# N32H7xx register map
Vendor: Nationstech Ltd.; File version: 1.0
CPU: CM7 r1p1, little endian, MPU, FPU, 4 interrupt priority bits
Registers are 32-bit, read-write, reset 0x0 unless marked. A register's access mark holds for its fields unless they carry their own. Offsets are from the block's base; [hi:lo] are bit positions; {n}, {i} and the like mark numbered series; 'fields as' and 'values as' point back to an identical list.

## AHB_CACHE_PARMON — AHB cache parity monitor
Base 0x40045000
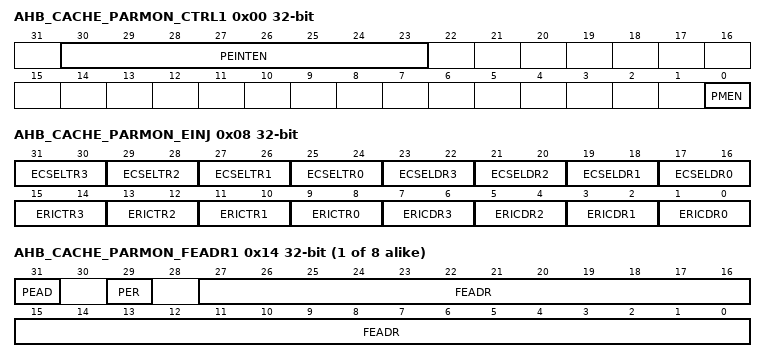
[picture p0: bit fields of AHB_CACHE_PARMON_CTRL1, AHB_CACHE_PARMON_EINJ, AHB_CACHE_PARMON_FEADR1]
0x00 AHB_CACHE_PARMON_CTRL1 — Parity monitor control register 1
  [30:23] PEINTEN, [0] PMEN
0x04 AHB_CACHE_PARMON_CTRL2 — Parity monitor control register 2
  [30:23] PFOEN
0x08 AHB_CACHE_PARMON_EINJ — Parity monitor error injection register
  [2n+25:2n+24] ECSELTR{n} (n=0..3), [2n+17:2n+16] ECSELDR{n} (n=0..3), [2n+9:2n+8] ERICTR{n} (n=0..3), [2n+1:2n] ERICDR{n} (n=0..3)
0x0C AHB_CACHE_PARMON_INTFS ro — Parity monitor interrupt flag shadow register
  [23:16] PEIF
0x10 AHB_CACHE_PARMON_INTF1 — Parity monitor memory 1 interrupt flag register
  [3] PEDCIFR
{0x0+0x14*i} AHB_CACHE_PARMON_FEADR{i} (i=1..8) — Parity monitor memory {i} fail event address register
  [31] PEAD, [29] PER, [27:0] FEADR ro
{0x4+0x14*i} AHB_CACHE_PARMON_FEDAT{i} ro (i=1..8) — Parity monitor memory {i} fail event data register
  [31:0] PEDAT
{0xC+0x14*i} AHB_CACHE_PARMON_FECOD{i} ro (i=1..8) — Parity monitor memory {i} fail event code register
  [15:0] PECOD
0x24 AHB_CACHE_PARMON_INTF2 — Parity monitor memory 2 interrupt flag register
  [3] PEDCIFR
0x38 AHB_CACHE_PARMON_INTF3 — Parity monitor memory 3 interrupt flag register
  [3] PEDCIFR
0x4C AHB_CACHE_PARMON_INTF4 — Parity monitor memory 4 interrupt flag register
  [3] PEDCIFR
0x60 AHB_CACHE_PARMON_INTF5 — Parity monitor memory 5 interrupt flag register
  [3] PEDCIFR
0x74 AHB_CACHE_PARMON_INTF6 — Parity monitor memory 6 interrupt flag register
  [3] PEDCIFR
0x88 AHB_CACHE_PARMON_INTF7 — Parity monitor memory 7 interrupt flag register
  [3] PEDCIFR
0x9C AHB_CACHE_PARMON_INTF8 — Parity monitor memory 8 interrupt flag register
  [3] PEDCIFR

## DMAMUX1 — DMA request multiplexer
Base 0x40046400
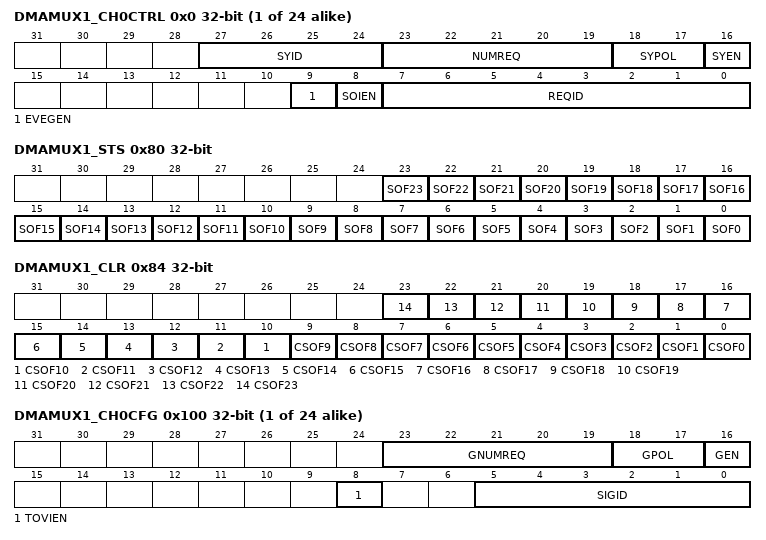
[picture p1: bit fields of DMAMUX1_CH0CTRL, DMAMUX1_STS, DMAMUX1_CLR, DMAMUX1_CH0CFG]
{0x0+4i} DMAMUX1_CH{i}CTRL (i=0..23) — nan
  [27:24] SYID, [23:19] NUMREQ, [18:17] SYPOL, [16] SYEN, [9] EVEGEN, [8] SOIEN, [7:0] REQID
0x80 DMAMUX1_STS ro — nan
  [n] SOF{n} (n=0..23)
0x84 DMAMUX1_CLR wo — nan
  [n] CSOF{n} (n=0..23)
{0x100+4i} DMAMUX1_CH{i}CFG (i=0..23) — nan
  [23:19] GNUMREQ, [18:17] GPOL, [16] GEN, [8] TOVIEN, [5:0] SIGID
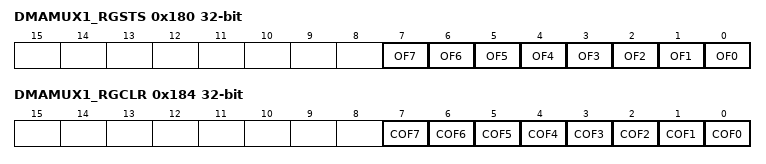
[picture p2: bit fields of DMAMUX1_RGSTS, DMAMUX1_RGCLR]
0x180 DMAMUX1_RGSTS ro — nan
  [n] OF{n} (n=0..7)
0x184 DMAMUX1_RGCLR wo — nan
  [n] COF{n} (n=0..7)

## DMAMUX2 — DMA request multiplexer
Base 0x51120000
Registers as DMAMUX1 (with DMAMUX1 read as DMAMUX2), without DMAMUX1_CH{n}CTRL (n=16..23), DMAMUX1_CH{n}CFG (n=16..23); these are added or differ:
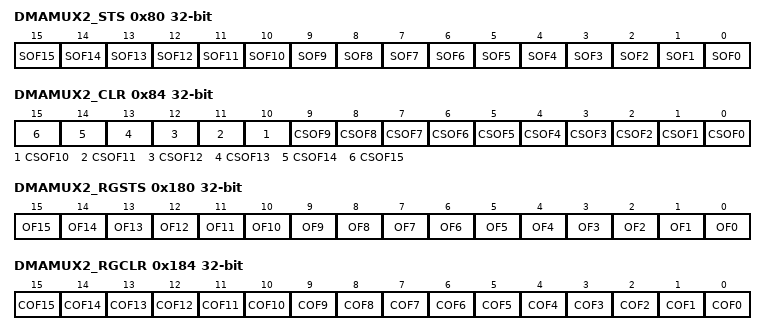
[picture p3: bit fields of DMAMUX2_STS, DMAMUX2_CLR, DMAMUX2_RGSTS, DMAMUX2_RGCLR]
0x80 DMAMUX2_STS ro — nan
  [n] SOF{n} (n=0..15)
0x84 DMAMUX2_CLR wo — nan
  [n] CSOF{n} (n=0..15)
0x180 DMAMUX2_RGSTS ro — nan
  [n] OF{n} (n=0..15)
0x184 DMAMUX2_RGCLR wo — nan
  [n] COF{n} (n=0..15)

## DMA1 — DMA controller 1
Base 0x40046800
Same registers: DMA2 0x40046C00, DMA3 0x40047000
{0x0+0x58*i} DMA_CH{i}SA (i=0..7)
  [31:0] ADDR
{0x8+0x58*i} DMA_CH{i}DA (i=0..7)
  [31:0] ADDR
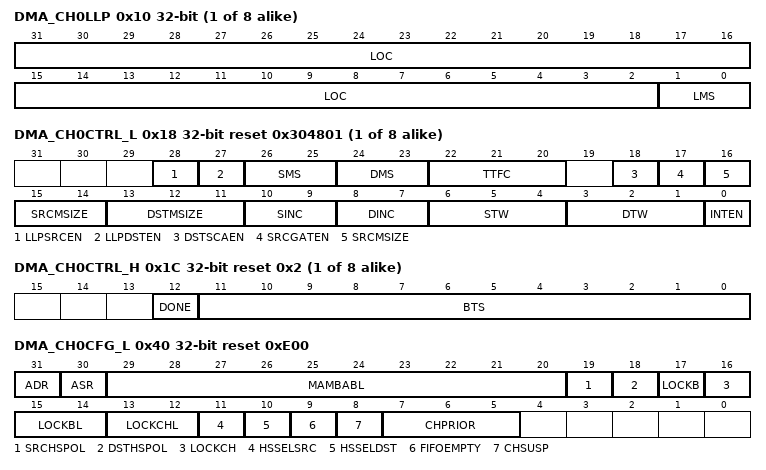
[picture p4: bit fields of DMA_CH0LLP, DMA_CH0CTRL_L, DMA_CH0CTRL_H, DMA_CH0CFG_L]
{0x10+0x58*i} DMA_CH{i}LLP (i=0..7)
  [31:2] LOC, [1:0] LMS
{0x18+0x58*i} DMA_CH{i}CTRL_L reset 0x304801 (i=0..7)
  [28] LLPSRCEN, [27] LLPDSTEN, [26:25] SMS, [24:23] DMS, [22:20] TTFC, [18] DSTSCAEN, [17] SRCGATEN, [16:14] SRCMSIZE, [13:11] DSTMSIZE, [10:9] SINC, [8:7] DINC, [6:4] STW, [3:1] DTW, [0] INTEN
{0x1C+0x58*i} DMA_CH{i}CTRL_H reset 0x2 (i=0..7)
  [12] DONE, [11:0] BTS
0x40 DMA_CH0CFG_L reset 0xE00
  [31] ADR, [30] ASR, [29:20] MAMBABL, [19] SRCHSPOL, [18] DSTHSPOL, [17] LOCKB, [16] LOCKCH, [15:14] LOCKBL, [13:12] LOCKCHL, [11] HSSELSRC, [10] HSSELDST, [9] FIFOEMPTY ro, [8] CHSUSP, [7:5] CHPRIOR
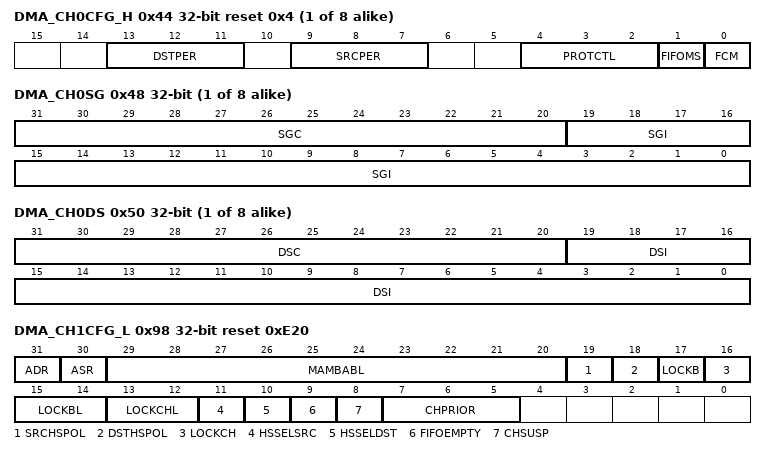
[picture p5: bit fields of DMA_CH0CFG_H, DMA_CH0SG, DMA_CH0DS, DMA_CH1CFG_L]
{0x44+0x58*i} DMA_CH{i}CFG_H reset 0x4 (i=0..7)
  [13:11] DSTPER, [9:7] SRCPER, [4:2] PROTCTL, [1] FIFOMS, [0] FCM
{0x48+0x58*i} DMA_CH{i}SG (i=0..7)
  [31:20] SGC, [19:0] SGI
{0x50+0x58*i} DMA_CH{i}DS (i=0..7)
  [31:20] DSC, [19:0] DSI
0x98 DMA_CH1CFG_L reset 0xE20
  fields as DMA_CH0CFG_L
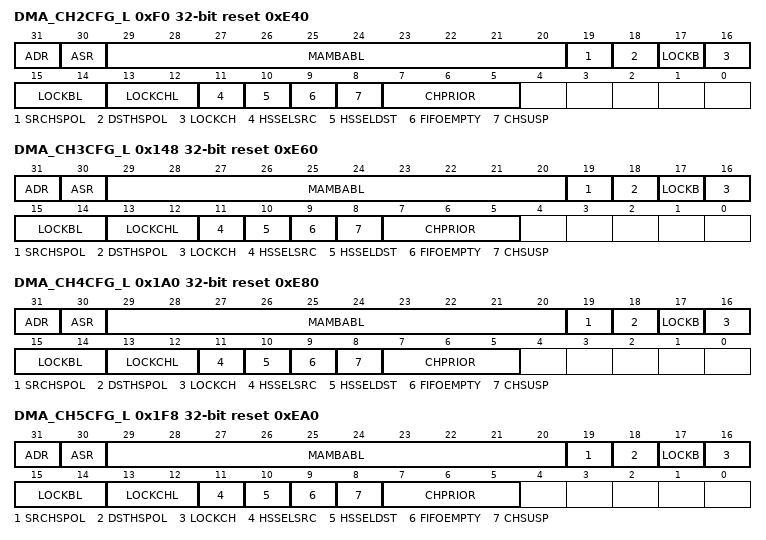
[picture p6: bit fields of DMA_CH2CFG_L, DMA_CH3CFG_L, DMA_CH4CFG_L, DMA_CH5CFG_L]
0xF0 DMA_CH2CFG_L reset 0xE40
  fields as DMA_CH0CFG_L
0x148 DMA_CH3CFG_L reset 0xE60
  fields as DMA_CH0CFG_L
0x1A0 DMA_CH4CFG_L reset 0xE80
  fields as DMA_CH0CFG_L
0x1F8 DMA_CH5CFG_L reset 0xEA0
  fields as DMA_CH0CFG_L
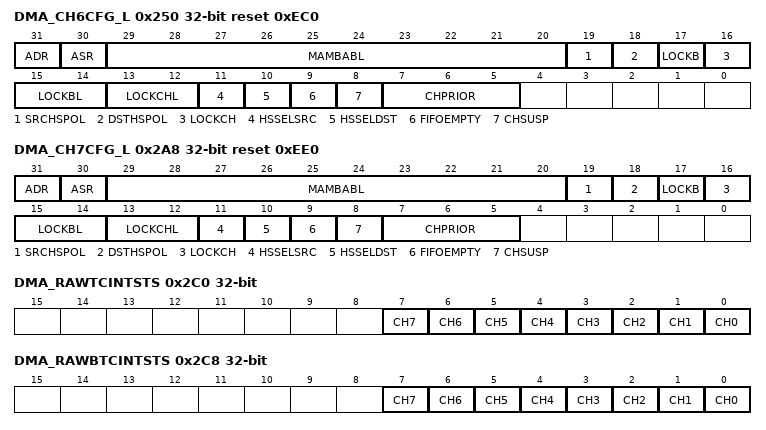
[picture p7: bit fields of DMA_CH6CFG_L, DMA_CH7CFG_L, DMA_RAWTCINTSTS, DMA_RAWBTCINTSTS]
0x250 DMA_CH6CFG_L reset 0xEC0
  fields as DMA_CH0CFG_L
0x2A8 DMA_CH7CFG_L reset 0xEE0
  fields as DMA_CH0CFG_L
0x2C0 DMA_RAWTCINTSTS
  [n] CH{n} (n=0..7)
0x2C8 DMA_RAWBTCINTSTS
  [n] CH{n} (n=0..7)
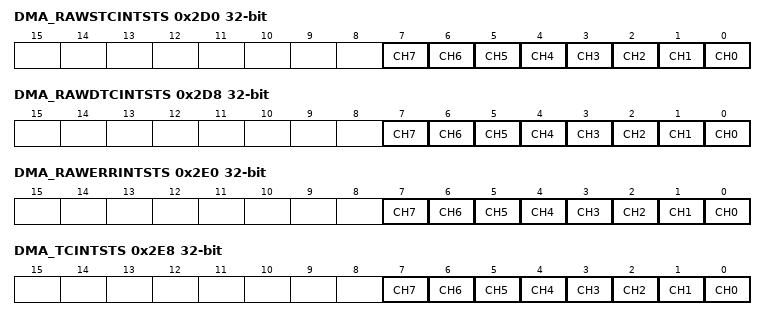
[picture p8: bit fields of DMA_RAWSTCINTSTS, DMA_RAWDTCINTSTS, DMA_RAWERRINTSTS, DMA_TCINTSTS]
0x2D0 DMA_RAWSTCINTSTS
  [n] CH{n} (n=0..7)
0x2D8 DMA_RAWDTCINTSTS
  [n] CH{n} (n=0..7)
0x2E0 DMA_RAWERRINTSTS
  [n] CH{n} (n=0..7)
0x2E8 DMA_TCINTSTS ro
  [n] CH{n} (n=0..7)
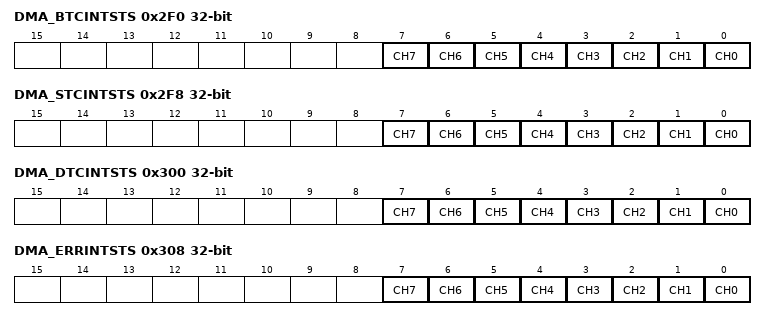
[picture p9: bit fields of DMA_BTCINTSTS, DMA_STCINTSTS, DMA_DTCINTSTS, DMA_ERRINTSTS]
0x2F0 DMA_BTCINTSTS ro
  [n] CH{n} (n=0..7)
0x2F8 DMA_STCINTSTS ro
  [n] CH{n} (n=0..7)
0x300 DMA_DTCINTSTS ro
  [n] CH{n} (n=0..7)
0x308 DMA_ERRINTSTS ro
  [n] CH{n} (n=0..7)
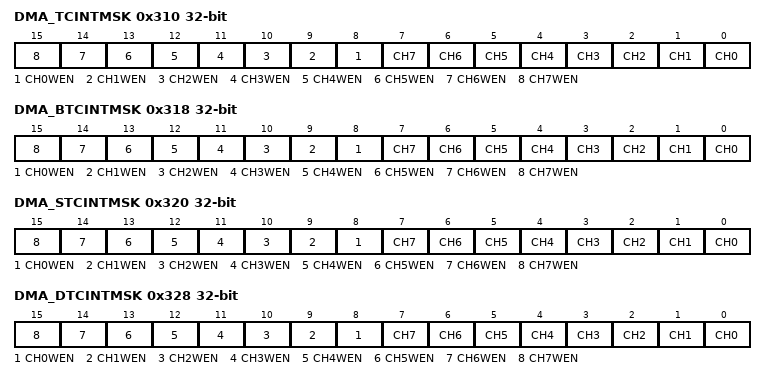
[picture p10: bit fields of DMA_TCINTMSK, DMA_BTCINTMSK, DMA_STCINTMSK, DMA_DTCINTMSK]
0x310 DMA_TCINTMSK
  [n+8] CH{n}WEN wo (n=0..7), [n] CH{n} (n=0..7)
0x318 DMA_BTCINTMSK
  [n+8] CH{n}WEN wo (n=0..7), [n] CH{n} (n=0..7)
0x320 DMA_STCINTMSK
  [n+8] CH{n}WEN wo (n=0..7), [n] CH{n} (n=0..7)
0x328 DMA_DTCINTMSK
  [n+8] CH{n}WEN wo (n=0..7), [n] CH{n} (n=0..7)
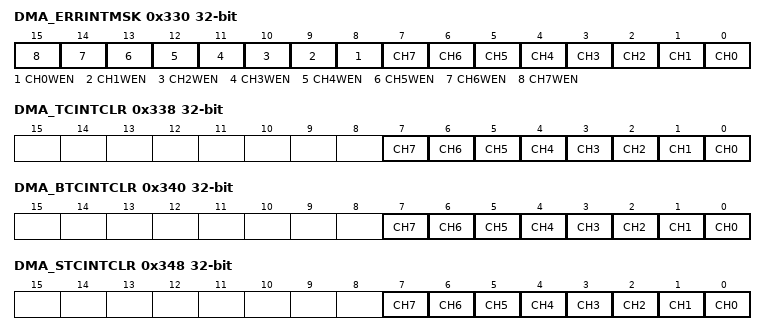
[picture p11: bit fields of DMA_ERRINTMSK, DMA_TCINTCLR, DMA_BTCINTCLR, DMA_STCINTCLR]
0x330 DMA_ERRINTMSK
  [n+8] CH{n}WEN wo (n=0..7), [n] CH{n} (n=0..7)
0x338 DMA_TCINTCLR wo
  [n] CH{n} (n=0..7)
0x340 DMA_BTCINTCLR wo
  [n] CH{n} (n=0..7)
0x348 DMA_STCINTCLR wo
  [n] CH{n} (n=0..7)
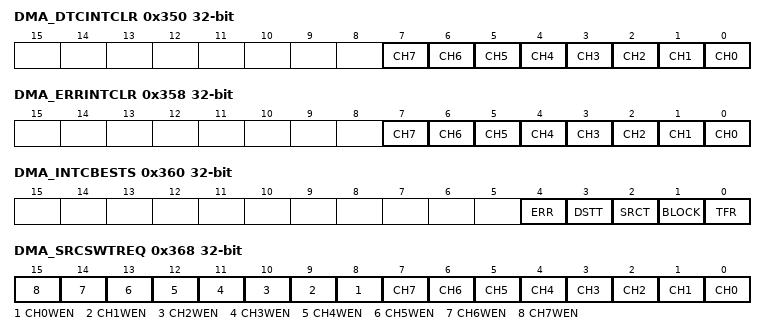
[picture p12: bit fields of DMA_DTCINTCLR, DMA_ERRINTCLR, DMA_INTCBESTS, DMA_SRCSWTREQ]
0x350 DMA_DTCINTCLR wo
  [n] CH{n} (n=0..7)
0x358 DMA_ERRINTCLR wo
  [n] CH{n} (n=0..7)
0x360 DMA_INTCBESTS ro
  [4] ERR, [3] DSTT, [2] SRCT, [1] BLOCK, [0] TFR
0x368 DMA_SRCSWTREQ
  [n+8] CH{n}WEN wo (n=0..7), [n] CH{n} (n=0..7)
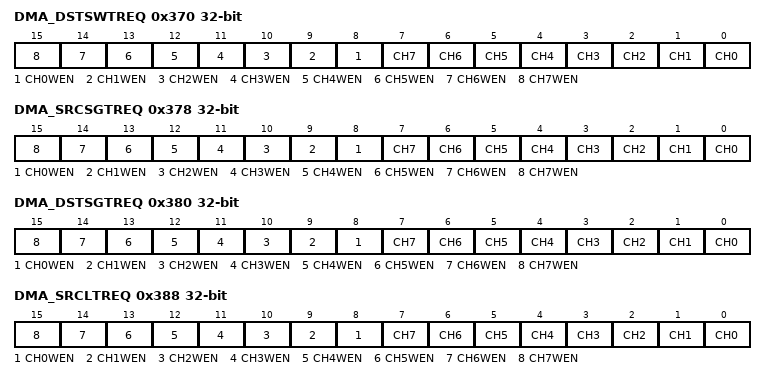
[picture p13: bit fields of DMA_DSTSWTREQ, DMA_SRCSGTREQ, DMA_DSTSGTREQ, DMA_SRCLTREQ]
0x370 DMA_DSTSWTREQ
  [n+8] CH{n}WEN wo (n=0..7), [n] CH{n} (n=0..7)
0x378 DMA_SRCSGTREQ
  [n+8] CH{n}WEN wo (n=0..7), [n] CH{n} (n=0..7)
0x380 DMA_DSTSGTREQ
  [n+8] CH{n}WEN wo (n=0..7), [n] CH{n} (n=0..7)
0x388 DMA_SRCLTREQ
  [n+8] CH{n}WEN wo (n=0..7), [n] CH{n} (n=0..7)
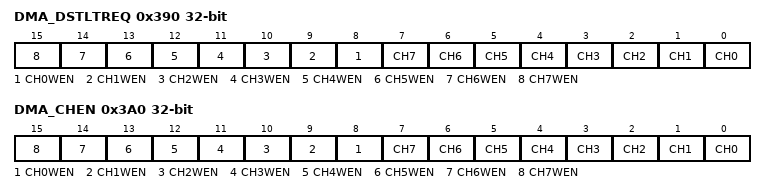
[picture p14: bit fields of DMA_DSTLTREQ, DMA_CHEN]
0x390 DMA_DSTLTREQ
  [n+8] CH{n}WEN wo (n=0..7), [n] CH{n} (n=0..7)
0x398 DMA_CFG
  [0] EN
0x3A0 DMA_CHEN
  [n+8] CH{n}WEN wo (n=0..7), [n] CH{n} (n=0..7)
0x3A8 DMA_ID ro
  [31:0] VALUE
0x3B0 DMA_TEST
  [0] TMS
0x3B8 DMA_LPTIMEOUT reset 0x8
  [7:0] VALUE
0x3F8 DMA_COMPID_L ro reset 0x44571110
  [31:0] TYPE
0x3FC DMA_COMPID_H ro reset 0x3232332A
  [31:0] VERSION
